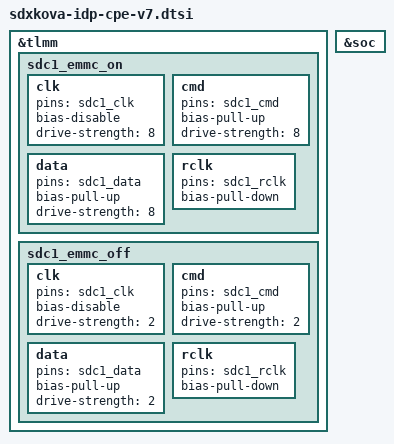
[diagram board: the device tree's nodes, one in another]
// SPDX-License-Identifier: BSD-3-Clause
/*
 * Copyright (c) Qualcomm Technologies, Inc. and/or its subsidiaries.
 */

#include "sdxkova-idp-cpe.dtsi"

&tlmm {
	sdc1_emmc_on: sdc1_emmc_on {
		clk {
			pins = "sdc1_clk";
			bias-disable;
			drive-strength = <8>;
		};

		cmd {
			pins = "sdc1_cmd";
			bias-pull-up;
			drive-strength = <8>;
		};

		data {
			pins = "sdc1_data";
			bias-pull-up;
			drive-strength = <8>;
		};

		rclk {
			pins = "sdc1_rclk";
			bias-pull-down;
		};
	};

	sdc1_emmc_off: sdc1_emmc_off {
		clk {
			pins = "sdc1_clk";
			bias-disable;
			drive-strength = <2>;
		};

		cmd {
			pins = "sdc1_cmd";
			bias-pull-up;
			drive-strength = <2>;
		};

		data {
			pins = "sdc1_data";
			bias-pull-up;
			drive-strength = <2>;
		};

		rclk {
			pins = "sdc1_rclk";
			bias-pull-down;
		};
	};
};

&soc {
};
